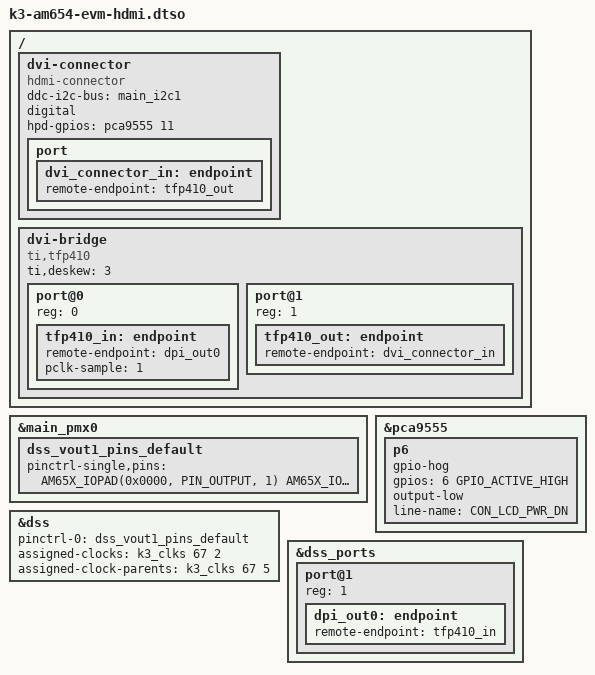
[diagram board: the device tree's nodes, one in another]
// SPDX-License-Identifier: GPL-2.0
/**
 * J6 PLUS HDMI DISPLAY ADAPTER for am654-evm (connected to J36)
 * Note: the USB is not connected on am654-evm
 *
 * Copyright (C) 2019 Texas Instruments Incorporated - http://www.ti.com/
 */

/dts-v1/;
/plugin/;

#include <dt-bindings/gpio/gpio.h>
#include <dt-bindings/interrupt-controller/irq.h>
#include <dt-bindings/pinctrl/k3.h>

/ {
  fragment@101 {
	target-path = "/";

	__overlay__ {
		dvi-connector {
			compatible = "hdmi-connector";
			ddc-i2c-bus = <&main_i2c1>;
			digital;

			/* the gpio doesn't support interrupt */
			hpd-gpios = <&pca9555 11 GPIO_ACTIVE_HIGH>;

			port {
				dvi_connector_in: endpoint {
					remote-endpoint = <&tfp410_out>;
				};
			};
		};

		dvi-bridge {
			#address-cells = <1>;
			#size-cells = <0>;
			compatible = "ti,tfp410";
			ti,deskew = <3>;

			port@0 {
				reg = <0>;

				tfp410_in: endpoint {
					remote-endpoint = <&dpi_out0>;
					pclk-sample = <1>;
				};
			};

			port@1 {
				reg = <1>;

				tfp410_out: endpoint {
					remote-endpoint = <&dvi_connector_in>;
				};
			};
		};
	};
  };
};

&main_pmx0 {
	dss_vout1_pins_default: dss_vout1_pins_default {
		pinctrl-single,pins = <
			AM65X_IOPAD(0x0000, PIN_OUTPUT, 1)	/* VOUT1_DATA0 */
			AM65X_IOPAD(0x0004, PIN_OUTPUT, 1)	/* VOUT1_DATA1 */
			AM65X_IOPAD(0x0008, PIN_OUTPUT, 1)	/* VOUT1_DATA2 */
			AM65X_IOPAD(0x000c, PIN_OUTPUT, 1)	/* VOUT1_DATA3 */
			AM65X_IOPAD(0x0010, PIN_OUTPUT, 1)	/* VOUT1_DATA4 */
			AM65X_IOPAD(0x0014, PIN_OUTPUT, 1)	/* VOUT1_DATA5 */
			AM65X_IOPAD(0x0018, PIN_OUTPUT, 1)	/* VOUT1_DATA6 */
			AM65X_IOPAD(0x001c, PIN_OUTPUT, 1)	/* VOUT1_DATA7 */
			AM65X_IOPAD(0x0020, PIN_OUTPUT, 1)	/* VOUT1_DATA8 */
			AM65X_IOPAD(0x0024, PIN_OUTPUT, 1)	/* VOUT1_DATA9 */
			AM65X_IOPAD(0x0028, PIN_OUTPUT, 1)	/* VOUT1_DATA10 */
			AM65X_IOPAD(0x002c, PIN_OUTPUT, 1)	/* VOUT1_DATA11 */
			AM65X_IOPAD(0x0030, PIN_OUTPUT, 1)	/* VOUT1_DATA12 */
			AM65X_IOPAD(0x0034, PIN_OUTPUT, 1)	/* VOUT1_DATA13 */
			AM65X_IOPAD(0x0038, PIN_OUTPUT, 1)	/* VOUT1_DATA14 */
			AM65X_IOPAD(0x003c, PIN_OUTPUT, 1)	/* VOUT1_DATA15 */
			AM65X_IOPAD(0x0040, PIN_OUTPUT, 1)	/* VOUT1_DATA16 */
			AM65X_IOPAD(0x0044, PIN_OUTPUT, 1)	/* VOUT1_DATA17 */
			AM65X_IOPAD(0x0048, PIN_OUTPUT, 1)	/* VOUT1_DATA18 */
			AM65X_IOPAD(0x004c, PIN_OUTPUT, 1)	/* VOUT1_DATA19 */
			AM65X_IOPAD(0x0050, PIN_OUTPUT, 1)	/* VOUT1_DATA20 */
			AM65X_IOPAD(0x0054, PIN_OUTPUT, 1)	/* VOUT1_DATA21 */
			AM65X_IOPAD(0x0058, PIN_OUTPUT, 1)	/* VOUT1_DATA22 */
			AM65X_IOPAD(0x005c, PIN_OUTPUT, 1)	/* VOUT1_DATA23 */
			AM65X_IOPAD(0x0060, PIN_OUTPUT, 1)	/* VOUT1_VSYNC */
			AM65X_IOPAD(0x0064, PIN_OUTPUT, 1)	/* VOUT1_HSYNC */
			AM65X_IOPAD(0x0068, PIN_OUTPUT, 1)	/* VOUT1_PCLK */
			AM65X_IOPAD(0x006c, PIN_OUTPUT, 1)	/* VOUT1_DE */
		>;
	};
};

&pca9555 {
	p6 {
		/* P06 - CON_LCD_PWR_DN */
		gpio-hog;
		gpios = <6 GPIO_ACTIVE_HIGH>;
		output-low;
		line-name = "CON_LCD_PWR_DN";
	};
};

&dss {
	status = "ok";

	pinctrl-names = "default";
	pinctrl-0 = <&dss_vout1_pins_default>;

	assigned-clocks = <&k3_clks 67 2>;
	assigned-clock-parents = <&k3_clks 67 5>;
};

&dss_ports {
	#address-cells = <1>;
	#size-cells = <0>;
	port@1 {
		reg = <1>;

		dpi_out0: endpoint {
			remote-endpoint = <&tfp410_in>;
		};
	};
};
